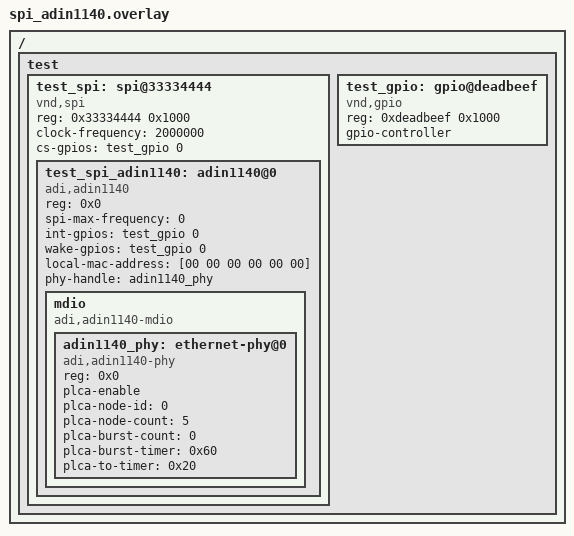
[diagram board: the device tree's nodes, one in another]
/*
 * Copyright (c) 2026 Mario Paja
 *
 * SPDX-License-Identifier: Apache-2.0
 *
 * ADIN1140 as the only driver using oa_tc6.c, so that it has to enable
 * everything it needs on its own.
 */

/ {
	test {
		#address-cells = <1>;
		#size-cells = <1>;

		test_spi: spi@33334444 {
			compatible = "vnd,spi";
			reg = <0x33334444 0x1000>;
			#address-cells = <1>;
			#size-cells = <0>;
			clock-frequency = <2000000>;
			cs-gpios = <&test_gpio 0 0>;
			status = "okay";

			test_spi_adin1140: adin1140@0 {
				compatible = "adi,adin1140";
				reg = <0x0>;
				spi-max-frequency = <0>;
				int-gpios = <&test_gpio 0 0>;
				wake-gpios = <&test_gpio 0 0>;
				local-mac-address = [00 00 00 00 00 00];
				phy-handle = <&adin1140_phy>;

				mdio {
					compatible = "adi,adin1140-mdio";
					#address-cells = <1>;
					#size-cells = <0>;

					adin1140_phy: ethernet-phy@0 {
						compatible = "adi,adin1140-phy";
						reg = <0x0>;
						plca-enable;
						plca-node-id = <0>;
						plca-node-count = <5>;
						plca-burst-count = <0>;
						plca-burst-timer = <0x60>;
						plca-to-timer = <0x20>;
						status = "okay";
					};
				};
			};
		};

		test_gpio: gpio@deadbeef {
			compatible = "vnd,gpio";
			reg = <0xdeadbeef 0x1000>;
			gpio-controller;
			#gpio-cells = <0x2>;
			status = "okay";
		};
	};
};
